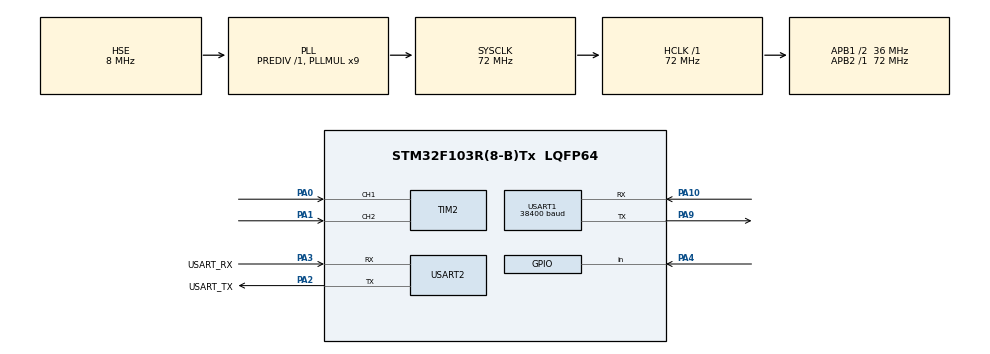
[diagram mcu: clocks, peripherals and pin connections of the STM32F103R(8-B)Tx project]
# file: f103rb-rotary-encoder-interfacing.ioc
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Mcu.Family=STM32F1
Mcu.Name=STM32F103R(8-B)Tx
Mcu.Package=LQFP64
NVIC.PriorityGroup=NVIC_PRIORITYGROUP_4
PA0-WKUP.Signal=S_TIM2_CH1_ETR
PA1.Signal=S_TIM2_CH2
PA10.Mode=Asynchronous
PA10.Signal=USART1_RX
PA13.GPIO_Label=TMS
PA13.Mode=Serial_Wire
PA13.Signal=SYS_JTMS-SWDIO
PA14.GPIO_Label=TCK
PA14.Mode=Serial_Wire
PA14.Signal=SYS_JTCK-SWCLK
PA2.GPIO_Label=USART_TX
PA2.GPIO_Mode=GPIO_MODE_AF_PP
PA2.GPIO_PuPd=GPIO_NOPULL
PA2.GPIO_Speed=GPIO_SPEED_FREQ_LOW
PA2.Mode=Asynchronous
PA2.Signal=USART2_TX
PA3.GPIO_Label=USART_RX
PA3.GPIO_Mode=GPIO_MODE_AF_PP
PA3.GPIO_PuPd=GPIO_NOPULL
PA3.GPIO_Speed=GPIO_SPEED_FREQ_LOW
PA3.Mode=Asynchronous
PA3.Signal=USART2_RX
PA4.Signal=GPIO_Input
PA9.Mode=Asynchronous
PA9.Signal=USART1_TX
PB3.GPIO_Label=SWO
PB3.Signal=SYS_JTDO-TRACESWO
PC14-OSC32_IN.Mode=LSE-External-Oscillator
PC14-OSC32_IN.Signal=RCC_OSC32_IN
PC15-OSC32_OUT.Mode=LSE-External-Oscillator
PC15-OSC32_OUT.Signal=RCC_OSC32_OUT
PD0-OSC_IN.Mode=HSE-External-Oscillator
PD0-OSC_IN.Signal=RCC_OSC_IN
PD1-OSC_OUT.Mode=HSE-External-Oscillator
PD1-OSC_OUT.Signal=RCC_OSC_OUT
ProjectManager.HeapSize=0x200
ProjectManager.StackSize=0x400
ProjectManager.TargetToolchain=STM32CubeIDE
RCC.AHBFreq_Value=72000000
RCC.APB1CLKDivider=RCC_HCLK_DIV2
RCC.APB1Freq_Value=36000000
RCC.APB1TimFreq_Value=72000000
RCC.APB2Freq_Value=72000000
RCC.APB2TimFreq_Value=72000000
RCC.HCLKFreq_Value=72000000
RCC.PLLMUL=RCC_PLL_MUL9
RCC.PLLSourceVirtual=RCC_PLLSOURCE_HSE
RCC.RTCClockSelection=RCC_RTCCLKSOURCE_LSE
RCC.SYSCLKFreq_VALUE=72000000
RCC.SYSCLKSource=RCC_SYSCLKSOURCE_PLLCLK
RCC.USBFreq_Value=72000000
SH.S_TIM2_CH1_ETR.0=TIM2_CH1,Encoder_Interface
SH.S_TIM2_CH2.0=TIM2_CH2,Encoder_Interface
TIM2.AutoReloadPreload=TIM_AUTORELOAD_PRELOAD_ENABLE
TIM2.EncoderMode=TIM_ENCODERMODE_TI12
TIM2.IC1Filter=10
USART1.BaudRate=38400
USART1.VirtualMode=VM_ASYNC
USART2.VirtualMode=VM_ASYNC
board=NUCLEO-F103RB

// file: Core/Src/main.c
/* USER CODE BEGIN Header */
/**
  ******************************************************************************
  * @file           : main.c
  * @brief          : Main program body
  ******************************************************************************
  * @attention
  *
  * Copyright (c) 2024 STMicroelectronics.
  * All rights reserved.
  *
  * This software is licensed under terms that can be found in the LICENSE file
  * in the root directory of this software component.
  * If no LICENSE file comes with this software, it is provided AS-IS.
  *
  ******************************************************************************
  */
/* USER CODE END Header */
#include "main.h"

/* USER CODE BEGIN Includes */
#include "stdio.h"
/* USER CODE END Includes */

TIM_HandleTypeDef htim2;

UART_HandleTypeDef huart1;
UART_HandleTypeDef huart2;

/* USER CODE BEGIN PV */
uint8_t x = 0;
/* USER CODE END PV */

void SystemClock_Config(void);
static void MX_GPIO_Init(void);
static void MX_TIM2_Init(void);
static void MX_USART1_UART_Init(void);
static void MX_USART2_UART_Init(void);

int main(void)
{
  /* USER CODE BEGIN 1 */
  uint8_t MSG[50] = {'\0'};
  /* USER CODE END 1 */

  /* MCU Configuration--------------------------------------------------------*/

  /* Reset of all peripherals, Initializes the Flash interface and the Systick. */
  HAL_Init();

  /* Configure the system clock */
  SystemClock_Config();

  /* Initialize all configured peripherals */
  MX_GPIO_Init();
  MX_TIM2_Init();
  MX_USART1_UART_Init();
  MX_USART2_UART_Init();
  /* USER CODE BEGIN 2 */
  HAL_TIM_Encoder_Start(&htim2, TIM_CHANNEL_ALL);
  /* USER CODE END 2 */

  /* Infinite loop */
  /* USER CODE BEGIN WHILE */
  while (1)
  {
    if (HAL_GPIO_ReadPin(GPIOA, GPIO_PIN_4)) {
      sprintf(MSG, "Encoder switch released, encoder ticks = %d\n\r", ((TIM2->CNT) >> 2));
      HAL_UART_Transmit(&huart1, MSG, sizeof(MSG), 100);
    } else {
      sprintf(MSG, "Encoder switch pressed, encoder ticks = %d\n\r", ((TIM2->CNT) >> 2));
      HAL_UART_Transmit(&huart1, MSG, sizeof(MSG), 100);
    }

    HAL_Delay(100);

    //C:\Program Files\STMicroelectronics\STM32Cube\STM32CubeProgrammer\bin
    //STM32_Programmer_CLI -c port=swd freq=4000 mode=normal -vb 3 -w C:\Users\Rob\Downloads\stm-codes\f103rb-rotary-encoder-interfacing\build\debug\build\f103rb-rotary-encoder-interfacing.bin 0x08000000 -s 0x08000000

    /* USER CODE END WHILE */

  }
}

void SystemClock_Config(void)
{
  RCC_OscInitTypeDef RCC_OscInitStruct = {0};
  RCC_ClkInitTypeDef RCC_ClkInitStruct = {0};

  /** Initializes the RCC Oscillators according to the specified parameters
  * in the RCC_OscInitTypeDef structure.
  */
  RCC_OscInitStruct.OscillatorType = RCC_OSCILLATORTYPE_HSE;
  RCC_OscInitStruct.HSEState = RCC_HSE_ON;
  RCC_OscInitStruct.HSEPredivValue = RCC_HSE_PREDIV_DIV1;
  RCC_OscInitStruct.HSIState = RCC_HSI_ON;
  RCC_OscInitStruct.PLL.PLLState = RCC_PLL_ON;
  RCC_OscInitStruct.PLL.PLLSource = RCC_PLLSOURCE_HSE;
  RCC_OscInitStruct.PLL.PLLMUL = RCC_PLL_MUL9;
  if (HAL_RCC_OscConfig(&RCC_OscInitStruct) != HAL_OK)
  {
    Error_Handler();
  }

  /** Initializes the CPU, AHB and APB buses clocks
  */
  RCC_ClkInitStruct.ClockType = RCC_CLOCKTYPE_HCLK|RCC_CLOCKTYPE_SYSCLK
                              |RCC_CLOCKTYPE_PCLK1|RCC_CLOCKTYPE_PCLK2;
  RCC_ClkInitStruct.SYSCLKSource = RCC_SYSCLKSOURCE_PLLCLK;
  RCC_ClkInitStruct.AHBCLKDivider = RCC_SYSCLK_DIV1;
  RCC_ClkInitStruct.APB1CLKDivider = RCC_HCLK_DIV2;
  RCC_ClkInitStruct.APB2CLKDivider = RCC_HCLK_DIV1;

  if (HAL_RCC_ClockConfig(&RCC_ClkInitStruct, FLASH_LATENCY_2) != HAL_OK)
  {
    Error_Handler();
  }
}

static void MX_TIM2_Init(void)
{

  TIM_Encoder_InitTypeDef sConfig = {0};
  TIM_MasterConfigTypeDef sMasterConfig = {0};

  htim2.Instance = TIM2;
  htim2.Init.Prescaler = 0;
  htim2.Init.CounterMode = TIM_COUNTERMODE_UP;
  htim2.Init.Period = 65535;
  htim2.Init.ClockDivision = TIM_CLOCKDIVISION_DIV1;
  htim2.Init.AutoReloadPreload = TIM_AUTORELOAD_PRELOAD_ENABLE;
  sConfig.EncoderMode = TIM_ENCODERMODE_TI12;
  sConfig.IC1Polarity = TIM_ICPOLARITY_RISING;
  sConfig.IC1Selection = TIM_ICSELECTION_DIRECTTI;
  sConfig.IC1Prescaler = TIM_ICPSC_DIV1;
  sConfig.IC1Filter = 10;
  sConfig.IC2Polarity = TIM_ICPOLARITY_RISING;
  sConfig.IC2Selection = TIM_ICSELECTION_DIRECTTI;
  sConfig.IC2Prescaler = TIM_ICPSC_DIV1;
  sConfig.IC2Filter = 0;
  if (HAL_TIM_Encoder_Init(&htim2, &sConfig) != HAL_OK)
  {
    Error_Handler();
  }
  sMasterConfig.MasterOutputTrigger = TIM_TRGO_RESET;
  sMasterConfig.MasterSlaveMode = TIM_MASTERSLAVEMODE_DISABLE;
  if (HAL_TIMEx_MasterConfigSynchronization(&htim2, &sMasterConfig) != HAL_OK)
  {
    Error_Handler();
  }

}

static void MX_USART1_UART_Init(void)
{

  huart1.Instance = USART1;
  huart1.Init.BaudRate = 38400;
  huart1.Init.WordLength = UART_WORDLENGTH_8B;
  huart1.Init.StopBits = UART_STOPBITS_1;
  huart1.Init.Parity = UART_PARITY_NONE;
  huart1.Init.Mode = UART_MODE_TX_RX;
  huart1.Init.HwFlowCtl = UART_HWCONTROL_NONE;
  huart1.Init.OverSampling = UART_OVERSAMPLING_16;
  if (HAL_UART_Init(&huart1) != HAL_OK)
  {
    Error_Handler();
  }

}

static void MX_USART2_UART_Init(void)
{

  huart2.Instance = USART2;
  huart2.Init.BaudRate = 115200;
  huart2.Init.WordLength = UART_WORDLENGTH_8B;
  huart2.Init.StopBits = UART_STOPBITS_1;
  huart2.Init.Parity = UART_PARITY_NONE;
  huart2.Init.Mode = UART_MODE_TX_RX;
  huart2.Init.HwFlowCtl = UART_HWCONTROL_NONE;
  huart2.Init.OverSampling = UART_OVERSAMPLING_16;
  if (HAL_UART_Init(&huart2) != HAL_OK)
  {
    Error_Handler();
  }

}

static void MX_GPIO_Init(void)
{
  GPIO_InitTypeDef GPIO_InitStruct = {0};

  /* GPIO Ports Clock Enable */
  __HAL_RCC_GPIOC_CLK_ENABLE();
  __HAL_RCC_GPIOD_CLK_ENABLE();
  __HAL_RCC_GPIOA_CLK_ENABLE();
  __HAL_RCC_GPIOB_CLK_ENABLE();

  /*Configure GPIO pin : PA4 */
  GPIO_InitStruct.Pin = GPIO_PIN_4;
  GPIO_InitStruct.Mode = GPIO_MODE_INPUT;
  GPIO_InitStruct.Pull = GPIO_NOPULL;
  HAL_GPIO_Init(GPIOA, &GPIO_InitStruct);

}

void Error_Handler(void)
{
  __disable_irq();
  while (1)
  {
  }
}
